AUTOSAR XML (schema 4.0)
standard types defined: float32, float64, sint16, sint32, sint8, uint16, uint32, uint8, void, boolean
package /ImplDataTypes
  impl type Impl_MultiStateBtnType: implementation-data-type=uint8, type-emitter=RTE
package /MappingSets
  data type mapping set MappingSet
package /PortInterfaces/SenderReceiver
  sender receiver interface SrIf_SeatCtrlBtns
    data HeightBtnState: type=Impl_MultiStateBtnType
    data SlideBtnState: type=Impl_MultiStateBtnType
    data inclineBtnState: type=Impl_MultiStateBtnType
  sender receiver interface SrIf_SeatCtrlData
    data Height: type=uint8
    data Incline: type=uint8
    data Slide: type=uint8
package /SoftwareComponents
  swc implementation Impl_SWC_HMI: programming-language=C, sw-version=1.0.0, vendor-id=255, behavior=Ibhv_SWC_HMI
    code-descriptors:
      code Code: artifact-descriptors=autosar-engineering-object={short-label=SWC.c, category=SWSRC}
    resource consumption ResourceConsumption
  swc implementation Impl_SWC_SeatManager: programming-language=C, sw-version=1.0.0, vendor-id=255, behavior=Ibhv_SWC_SeatManager
    code-descriptors:
      code Code: artifact-descriptors=autosar-engineering-object={short-label=SWC.c, category=SWSRC}
    resource consumption ResourceConsumption
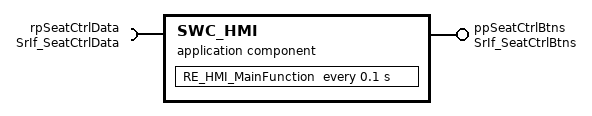
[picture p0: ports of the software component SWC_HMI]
  application sw component type SWC_HMI
    provide port ppSeatCtrlBtns: provided-interface=SrIf_SeatCtrlBtns
    require port rpSeatCtrlData: required-interface=SrIf_SeatCtrlData
    behavior Ibhv_SWC_HMI: data-type-mapping=MappingSet, handle-termination-and-restart=NO-SUPPORT
      timing event TE_RE_HMI_MainFunction_100ms: start-on-event=RE_HMI_MainFunction, period=0.1
      runnable RE_HMI_MainFunction
        data-receive-point-by-arguments:
          access DRP_rpSeatCtrlData_Height: accessed-variable=rpSeatCtrlData.Height
          access DRP_rpSeatCtrlData_Incline: accessed-variable=rpSeatCtrlData.Incline
          access DRP_rpSeatCtrlData_Slide: accessed-variable=rpSeatCtrlData.Slide
        data-send-points:
          access DSP_ppSeatCtrlBtns_HeightBtnState: accessed-variable=ppSeatCtrlBtns.HeightBtnState
          access DSP_ppSeatCtrlBtns_SlideBtnState: accessed-variable=ppSeatCtrlBtns.SlideBtnState
          access DSP_ppSeatCtrlBtns_inclineBtnState: accessed-variable=ppSeatCtrlBtns.inclineBtnState
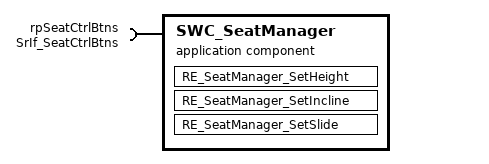
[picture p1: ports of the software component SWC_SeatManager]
  application sw component type SWC_SeatManager
    require port rpSeatCtrlBtns: required-interface=SrIf_SeatCtrlBtns
    behavior Ibhv_SWC_SeatManager: data-type-mapping=MappingSet, handle-termination-and-restart=NO-SUPPORT
      data received event DRE_rpSeatCtrlBtns_HeightBtnState: start-on-event=RE_SeatManager_SetHeight, data=rpSeatCtrlBtns.HeightBtnState
      data received event DRE_rpSeatCtrlBtns_SlideBtnState: start-on-event=RE_SeatManager_SetSlide, data=rpSeatCtrlBtns.SlideBtnState
      data received event DRE_rpSeatCtrlBtns_inclineBtnState: start-on-event=RE_SeatManager_SetIncline, data=rpSeatCtrlBtns.inclineBtnState
      runnable RE_SeatManager_SetHeight
        data-receive-point-by-arguments:
          access DRP_rpSeatCtrlBtns_HeightBtnState: accessed-variable=rpSeatCtrlBtns.HeightBtnState
      runnable RE_SeatManager_SetIncline
        data-receive-point-by-arguments:
          access DRP_rpSeatCtrlBtns_inclineBtnState: accessed-variable=rpSeatCtrlBtns.inclineBtnState
      runnable RE_SeatManager_SetSlide
        data-receive-point-by-arguments:
          access DRP_rpSeatCtrlBtns_SlideBtnState: accessed-variable=rpSeatCtrlBtns.SlideBtnState
package /Compositions
  composition sw component type Sender-ReciverComposition
    component SWC_HMI: type=SWC_HMI
    component SWC_SeatManager: type=SWC_SeatManager
    connect SWC_HMI.ppSeatCtrlBtns -> SWC_SeatManager.rpSeatCtrlBtns
